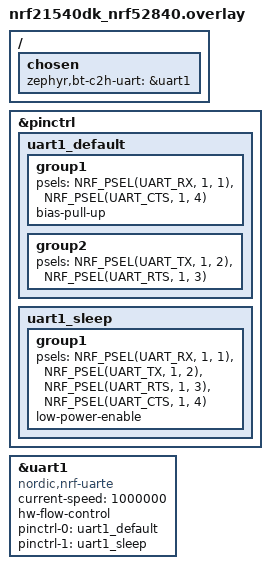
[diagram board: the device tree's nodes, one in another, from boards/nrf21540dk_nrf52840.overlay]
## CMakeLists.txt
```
# SPDX-License-Identifier: Apache-2.0

cmake_minimum_required(VERSION 3.20.0)

find_package(Zephyr REQUIRED HINTS $ENV{ZEPHYR_BASE})
project(hci_uart)

target_sources(app PRIVATE src/main.c src/status_leds.c)
```

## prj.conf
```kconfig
CONFIG_CONSOLE=n
CONFIG_STDOUT_CONSOLE=n
CONFIG_UART_CONSOLE=n
CONFIG_GPIO=y
CONFIG_SERIAL=y
CONFIG_UART_INTERRUPT_DRIVEN=y

CONFIG_SYSTEM_WORKQUEUE_STACK_SIZE=512

CONFIG_BT=y
CONFIG_BT_HCI_RAW=y
CONFIG_BT_HCI_RAW_H4=y
CONFIG_BT_HCI_RAW_H4_ENABLE=y
CONFIG_BT_MAX_CONN=16

# NOTE: this NCS/Zephyr version has no assignable CONFIG_BT_CTLR symbol
# (Kconfig error: "undefined symbol BT_CTLR"). The umbrella symbol is now
# the hidden CONFIG_HAS_BT_CTLR, auto-selected by whichever link-layer
# implementation is active; it is not user-settable. For nrf52840dk/
# nrf52840 in this tree the active controller is the Nordic SoftDevice
# Controller (DT node bt_hci_sdc, chosen as zephyr,bt-hci), selected
# automatically because DT_HAS_NORDIC_BT_HCI_SDC_ENABLED and
# SOC_SERIES_NRF52 are true - no prj.conf entry needed to enable it.
CONFIG_BT_CTLR_ASSERT_HANDLER=y

# CONFIG_BT_OBSERVER has no default-y-if-BT_HCI_RAW (unlike BT_CENTRAL/
# BT_PERIPHERAL): without it, passive scanning is not even compiled in,
# and CONFIG_BT_CTLR_SDC_SCAN_BUFFER_COUNT below stays inert (it depends
# on BT_OBSERVER).
CONFIG_BT_OBSERVER=y

# BT_CENTRAL/BT_PERIPHERAL both have default-y-if-BT_HCI_RAW already, so
# this is technically redundant, but made explicit: this firmware covers
# passive scan monitoring (Observer), the host (BlueZ) initiating GATT
# connections to discovered devices (Central), advertising so the host
# can be discovered (Broadcaster), and accepting incoming GATT
# connections (Peripheral).
CONFIG_BT_CENTRAL=y
CONFIG_BT_PERIPHERAL=y
CONFIG_BT_BROADCASTER=y

# Default TX power at boot: +8 dBm, the maximum the bare nRF52840 RADIO
# peripheral can produce (confirmed against the official register
# definition in nrf52840_bitfields.h - RADIO_TXPOWER_TXPOWER_Pos8dBm is
# the highest positive enumerator; there is no +9/+10 dBm on this chip).
# Previously left at the Kconfig default of 0 dBm.
CONFIG_BT_CTLR_TX_PWR_PLUS_8=y

# Exposes the Zephyr/Nordic vendor-specific "Read/Write TX Power Level"
# HCI commands (opcodes 0xFC0F/0xFC0E) at runtime, per connection/role
# handle. Without this, TX power is fixed at build time and those VS
# commands are rejected by the controller as Unknown HCI Command
# (status 0x01) - confirmed on hardware. Needed because BlueZ manages
# GATT connections to discovered devices and may want to tune TX power
# per link (range vs. power trade-off) rather than live with one fixed
# value for everything; also relevant once a future nRF21540 FEM
# iteration needs its own runtime power control up to +20/+21 dBm.
CONFIG_BT_CTLR_TX_PWR_DYNAMIC_CONTROL=y

# Sizing for continuous passive-scan monitoring (many devices, sustained
# LE Advertising Report stream), not generic/bursty usage:
#
# Controller-internal scan buffers (SoftDevice Controller, the active
# controller for nrf52840dk/nrf52840 in this NCS tree via the bt_hci_sdc
# DT node). These hold incoming packets/advertising reports before they
# become HCI events queued for the H4 UART driver. Raised from the
# default of 3 to the maximum of 20 to absorb bursts of overlapping
# adverts from many nearby devices without the controller dropping
# reports; cost is a few KB of RAM (~255 B/buffer worst case).
CONFIG_BT_CTLR_SDC_SCAN_BUFFER_COUNT=20

# Host-side HCI event RX queue, matched to the controller buffer count
# above per the sample's own guidance ("adjust to match Controller
# values"). This is the last stage before events are drained onto the
# UART; at the default of 10 it is the first thing to overflow under a
# sustained multi-device advertising burst. Raised to the Kconfig
# maximum (255) since this firmware's whole purpose is absorbing bursty
# advertising traffic, and the extra RAM (up to ~255 x 255 B if events
# are max-sized) is cheap compared to silently losing reports.
CONFIG_BT_BUF_EVT_RX_COUNT=255

# Maximum HCI event buffer length: raised to 255 (from the 68-byte
# default that applies without BT_EXT_ADV) so extended-advertising
# reports (long AD payloads) are never truncated.
CONFIG_BT_BUF_EVT_RX_SIZE=255
```

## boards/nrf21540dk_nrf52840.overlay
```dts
/* SPDX-License-Identifier: Apache-2.0 */

/*
 * Same HCI link as on the nRF52840-DK: uart1 at 1 Mbaud with hardware flow
 * control, uart0 left for the debug console.
 *
 * The nRF21540-DK carries an nRF52840 as its SoC, and its uart1 pinctrl is
 * identical to the plain DK's - RX on P1.01, TX on P1.02, no RTS/CTS - so
 * the same pins and the same wiring to the Pi apply. RTS/CTS are added here
 * on P1.03/P1.04, silkscreened D2/D3 on the Arduino header.
 *
 * The FEM itself needs nothing here: the board devicetree already declares
 * nrf_radio_fem with its control GPIOs (P0.17/19/20/21/22/23) and SPI, all
 * on port 0 and spi3, so nothing collides with the UART on port 1.
 */

/ {
	chosen {
		zephyr,bt-c2h-uart = &uart1;
	};
};

&pinctrl {
	uart1_default: uart1_default {
		group1 {
			psels = <NRF_PSEL(UART_RX, 1, 1)>,
				<NRF_PSEL(UART_CTS, 1, 4)>;
			bias-pull-up;
		};

		group2 {
			psels = <NRF_PSEL(UART_TX, 1, 2)>,
				<NRF_PSEL(UART_RTS, 1, 3)>;
		};
	};

	uart1_sleep: uart1_sleep {
		group1 {
			psels = <NRF_PSEL(UART_RX, 1, 1)>,
				<NRF_PSEL(UART_TX, 1, 2)>,
				<NRF_PSEL(UART_RTS, 1, 3)>,
				<NRF_PSEL(UART_CTS, 1, 4)>;
			low-power-enable;
		};
	};
};

&uart1 {
	compatible = "nordic,nrf-uarte";
	status = "okay";
	current-speed = <1000000>;
	hw-flow-control;
	pinctrl-0 = <&uart1_default>;
	pinctrl-1 = <&uart1_sleep>;
	pinctrl-names = "default", "sleep";
};
```

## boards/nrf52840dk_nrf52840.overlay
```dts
/* SPDX-License-Identifier: Apache-2.0 */

/*
 * HCI link to the Raspberry Pi runs on uart1, not uart0.
 * uart0 stays free for the J-Link virtual COM port (debug console),
 * kept separate from the physical HCI link.
 *
 * uart1 default pinctrl (nrf52840dk_nrf52840-pinctrl.dtsi) only assigns
 * RX (P1.01) and TX (P1.02); RTS/CTS are not present there and are added
 * below on P1.03 / P1.04. Chosen over P1.00/P1.09 (also free) because
 * P1.03/P1.04 are silkscreened on the DK's Arduino header as D2/D3,
 * making them easy to identify physically; D2/D3 are not used by any
 * on-board peripheral (SPI3 uses D11-D13, i.e. P1.13-15).
 */

/ {
	chosen {
		zephyr,bt-c2h-uart = &uart1;
	};
};

&pinctrl {
	uart1_default: uart1_default {
		group1 {
			psels = <NRF_PSEL(UART_RX, 1, 1)>,
				<NRF_PSEL(UART_CTS, 1, 4)>;
			bias-pull-up;
		};

		group2 {
			psels = <NRF_PSEL(UART_TX, 1, 2)>,
				<NRF_PSEL(UART_RTS, 1, 3)>;
		};
	};

	uart1_sleep: uart1_sleep {
		group1 {
			psels = <NRF_PSEL(UART_RX, 1, 1)>,
				<NRF_PSEL(UART_TX, 1, 2)>,
				<NRF_PSEL(UART_RTS, 1, 3)>,
				<NRF_PSEL(UART_CTS, 1, 4)>;
			low-power-enable;
		};
	};
};

&uart1 {
	compatible = "nordic,nrf-uarte";
	status = "okay";
	current-speed = <1000000>;
	hw-flow-control;
	pinctrl-0 = <&uart1_default>;
	pinctrl-1 = <&uart1_sleep>;
	pinctrl-names = "default", "sleep";
};
```

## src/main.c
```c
/*
 * Copyright (c) 2016 Nordic Semiconductor ASA
 * Copyright (c) 2015-2016 Intel Corporation
 *
 * SPDX-License-Identifier: Apache-2.0
 */

#include <errno.h>
#include <stddef.h>
#include <stdio.h>
#include <string.h>

#include <zephyr/kernel.h>
#include <zephyr/arch/cpu.h>
#include <zephyr/sys/byteorder.h>
#include <zephyr/logging/log_ctrl.h>
#include <zephyr/logging/log.h>
#include <zephyr/sys/util.h>

#include <zephyr/device.h>
#include <zephyr/init.h>
#include <zephyr/drivers/uart.h>

#include <zephyr/net_buf.h>
#include <zephyr/bluetooth/bluetooth.h>
#include <zephyr/bluetooth/l2cap.h>
#include <zephyr/bluetooth/hci.h>
#include <zephyr/bluetooth/buf.h>
#include <zephyr/bluetooth/hci_raw.h>
#include <zephyr/bluetooth/hci_vs.h>

#include "status_leds.h"

#define LOG_MODULE_NAME hci_uart
LOG_MODULE_REGISTER(LOG_MODULE_NAME);

static const struct device *const hci_uart_dev =
	DEVICE_DT_GET(DT_CHOSEN(zephyr_bt_c2h_uart));
static K_THREAD_STACK_DEFINE(tx_thread_stack, CONFIG_BT_HCI_TX_STACK_SIZE);
static struct k_thread tx_thread_data;
static K_FIFO_DEFINE(tx_queue);

/* RX in terms of bluetooth communication */
static K_FIFO_DEFINE(uart_tx_queue);

#define H4_CMD 0x01
#define H4_ACL 0x02
#define H4_SCO 0x03
#define H4_EVT 0x04
#define H4_ISO 0x05

/* Receiver states. */
#define ST_IDLE 0	/* Waiting for packet type. */
#define ST_HDR 1	/* Receiving packet header. */
#define ST_PAYLOAD 2	/* Receiving packet payload. */
#define ST_DISCARD 3	/* Dropping packet. */

/* Length of a discard/flush buffer.
 * This is sized to align with a Bluetooth HCI packet:
 * 1 byte H:4 header + 32 bytes ACL/event data
 * Bigger values might overflow the stack since this is declared as a local
 * variable, smaller ones will force the caller to call into discard more
 * often.
 */
#define H4_DISCARD_LEN 33

static int h4_read(const struct device *uart, uint8_t *buf, size_t len)
{
	int rx = uart_fifo_read(uart, buf, len);

	LOG_DBG("read %d req %d", rx, len);

	return rx;
}

static bool valid_type(uint8_t type)
{
	return (type == H4_CMD) | (type == H4_ACL) | (type == H4_ISO);
}

/* Function expects that type is validated and only CMD, ISO or ACL will be used. */
static uint32_t get_len(const uint8_t *hdr_buf, uint8_t type)
{
	switch (type) {
	case H4_CMD:
		return ((const struct bt_hci_cmd_hdr *)hdr_buf)->param_len;
	case H4_ISO:
		return bt_iso_hdr_len(
			sys_le16_to_cpu(((const struct bt_hci_iso_hdr *)hdr_buf)->len));
	case H4_ACL:
		return sys_le16_to_cpu(((const struct bt_hci_acl_hdr *)hdr_buf)->len);
	default:
		LOG_ERR("Invalid type: %u", type);
		return 0;
	}
}

/* Function expects that type is validated and only CMD, ISO or ACL will be used. */
static int hdr_len(uint8_t type)
{
	switch (type) {
	case H4_CMD:
		return sizeof(struct bt_hci_cmd_hdr);
	case H4_ISO:
		return sizeof(struct bt_hci_iso_hdr);
	case H4_ACL:
		return sizeof(struct bt_hci_acl_hdr);
	default:
		LOG_ERR("Invalid type: %u", type);
		return 0;
	}
}

static void rx_isr(void)
{
	static struct net_buf *buf;
	static int remaining;
	static uint8_t state;
	static uint8_t type;
	static uint8_t hdr_buf[MAX(sizeof(struct bt_hci_cmd_hdr),
			sizeof(struct bt_hci_acl_hdr))];
	int read;

	do {
		switch (state) {
		case ST_IDLE:
			/* Get packet type */
			read = h4_read(hci_uart_dev, &type, sizeof(type));
			/* since we read in loop until no data is in the fifo,
			 * it is possible that read = 0.
			 */
			if (read) {
				if (valid_type(type)) {
					status_leds_rx_activity();
					/* Get expected header size and switch
					 * to receiving header.
					 */
					remaining = hdr_len(type);
					state = ST_HDR;
				} else {
					LOG_WRN("Unknown header %d", type);
				}
			}
			break;
		case ST_HDR:
			read = h4_read(hci_uart_dev,
				       &hdr_buf[hdr_len(type) - remaining],
				       remaining);
			remaining -= read;
			if (remaining == 0) {
				/* Header received. Allocate buffer and get
				 * payload length. If allocation fails leave
				 * interrupt. On failed allocation state machine
				 * is reset.
				 */
				buf = bt_buf_get_tx(bt_buf_type_from_h4(type, BT_BUF_OUT),
						    K_NO_WAIT, NULL, 0);
				if (!buf) {
					LOG_ERR("No available command buffers!");
					state = ST_IDLE;
					return;
				}

				remaining = get_len(hdr_buf, type);

				net_buf_add_mem(buf, hdr_buf, hdr_len(type));
				if (remaining > net_buf_tailroom(buf)) {
					LOG_ERR("Not enough space in buffer");
					net_buf_unref(buf);
					state = ST_DISCARD;
				} else {
					state = ST_PAYLOAD;
				}

			}
			break;
		case ST_PAYLOAD:
			read = h4_read(hci_uart_dev, net_buf_tail(buf),
				       remaining);
			buf->len += read;
			remaining -= read;
			if (remaining == 0) {
				/* Packet received */
				LOG_DBG("putting RX packet in queue.");
				k_fifo_put(&tx_queue, buf);
				state = ST_IDLE;
			}
			break;
		case ST_DISCARD:
		{
			uint8_t discard[H4_DISCARD_LEN];
			size_t to_read = MIN(remaining, sizeof(discard));

			read = h4_read(hci_uart_dev, discard, to_read);
			remaining -= read;
			if (remaining == 0) {
				state = ST_IDLE;
			}

			break;

		}
		default:
			read = 0;
			__ASSERT_NO_MSG(0);
			break;

		}
	} while (read);
}

static void tx_isr(void)
{
	static struct net_buf *buf;
	int len;

	if (!buf) {
		buf = k_fifo_get(&uart_tx_queue, K_NO_WAIT);
		if (!buf) {
			uart_irq_tx_disable(hci_uart_dev);
			return;
		}
	}

	len = uart_fifo_fill(hci_uart_dev, buf->data, buf->len);
	net_buf_pull(buf, len);
	if (!buf->len) {
		net_buf_unref(buf);
		buf = NULL;
	}
}

static void bt_uart_isr(const struct device *unused, void *user_data)
{
	ARG_UNUSED(unused);
	ARG_UNUSED(user_data);

	while (true) {
		uart_irq_update(hci_uart_dev);

		if (uart_irq_is_pending(hci_uart_dev) <= 0) {
			break;
		}

		if (!(uart_irq_rx_ready(hci_uart_dev) ||
		      uart_irq_tx_ready(hci_uart_dev))) {
			LOG_DBG("spurious interrupt");
		}

		if (uart_irq_tx_ready(hci_uart_dev)) {
			tx_isr();
		}

		if (uart_irq_rx_ready(hci_uart_dev)) {
			rx_isr();
		}
	}
}

static void tx_thread(void *p1, void *p2, void *p3)
{
	while (1) {
		struct net_buf *buf;
		int err;

		/* Wait until a buffer is available */
		buf = k_fifo_get(&tx_queue, K_FOREVER);
		/* Pass buffer to the stack */
		err = bt_send(buf);
		if (err) {
			LOG_ERR("Unable to send (err %d)", err);
			net_buf_unref(buf);
		}

		/* Give other threads a chance to run if tx_queue keeps getting
		 * new data all the time.
		 */
		k_yield();
	}
}

/* Light LED4 on every LE Advertising Report leaving for the host, so radio
 * reception is observable on the board itself. Layout at this point is the
 * on-wire H4 frame: [0] H4 type, [1] event code, [2] param len, [3] LE
 * subevent code.
 */
static void led_flash_if_adv_report(const struct net_buf *buf)
{
	if (buf->len < 4) {
		return;
	}

	if (buf->data[0] != H4_EVT ||
	    buf->data[1] != BT_HCI_EVT_LE_META_EVENT) {
		return;
	}

	if (buf->data[3] == BT_HCI_EVT_LE_ADVERTISING_REPORT ||
	    buf->data[3] == BT_HCI_EVT_LE_EXT_ADVERTISING_REPORT) {
		status_leds_adv_report();
	}
}

static int h4_send(struct net_buf *buf)
{
	LOG_DBG("buf %p type %u len %u", buf, buf->data[0], buf->len);

	led_flash_if_adv_report(buf);
	status_leds_tx_activity();

	k_fifo_put(&uart_tx_queue, buf);
	uart_irq_tx_enable(hci_uart_dev);

	return 0;
}

#if defined(CONFIG_BT_CTLR_ASSERT_HANDLER)
void bt_ctlr_assert_handle(char *file, uint32_t line)
{
	/* Disable interrupts, this is unrecoverable */
	(void)irq_lock();

	if (IS_ENABLED(CONFIG_BT_HCI_VS_FATAL_ERROR)) {
		struct net_buf *buf;

		/* Prepare vendor specific HCI error event */
		buf = hci_vs_err_assert(file, line);
		if (buf != NULL) {
			uint32_t len;
			uint8_t *data;

			/* Disable interrupt driven, and use polling to be able to transmit while
			 * being in highest priority ISR.
			 */
			uart_irq_rx_disable(hci_uart_dev);
			uart_irq_tx_disable(hci_uart_dev);

			/* Send the event over UART */
			data = &buf->data[0];
			len = buf->len;
			while (len) {
				uart_poll_out(hci_uart_dev, *data);
				data++;
				len--;
			}
		} else {
			LOG_ERR("Can't create Fatal Error HCI event: %s at %d", __FILE__, __LINE__);
		}

		LOG_ERR("Halting system");
	} else {
		LOG_ERR("Controller assert in: %s at %d", file, line);
	}

	/* Flush the logs before locking the CPU */
	LOG_PANIC();

	while (true) {
		k_cpu_idle();
	};

	CODE_UNREACHABLE;
}
#endif /* CONFIG_BT_CTLR_ASSERT_HANDLER */

#if defined(CONFIG_BT_HCI_VS_FATAL_ERROR)
void k_sys_fatal_error_handler(unsigned int reason, const struct arch_esf *esf)
{
	/* Disable interrupts, this is unrecoverable */
	(void)irq_lock();

	/* Generate an error event only when there is a stack frame */
	if (esf != NULL) {
		struct net_buf *buf;

		/* Prepare vendor specific HCI error event */
		buf = hci_vs_err_stack_frame(reason, esf);
		if (buf != NULL) {
			uint32_t len;
			uint8_t *data;

			/* Disable interrupt driven, and use polling to be able to transmit while
			 * being in highest priority ISR.
			 */
			uart_irq_rx_disable(hci_uart_dev);
			uart_irq_tx_disable(hci_uart_dev);

			/* Send the event over UART */
			data = &buf->data[0];
			len = buf->len;
			while (len) {
				uart_poll_out(hci_uart_dev, *data);
				data++;
				len--;
			}
		} else {
			LOG_ERR("Can't create Fatal Error HCI event.\n");
		}
	}

	LOG_ERR("Halting system");

	/* Flush the logs before locking the CPU */
	LOG_PANIC();

	while (true) {
		k_cpu_idle();
	};

	CODE_UNREACHABLE;
}
#endif /* CONFIG_BT_HCI_VS_FATAL_ERROR */

static int hci_uart_init(void)
{
	LOG_DBG("");

	if (!device_is_ready(hci_uart_dev)) {
		LOG_ERR("HCI UART %s is not ready", hci_uart_dev->name);
		return -EINVAL;
	}

	uart_irq_rx_disable(hci_uart_dev);
	uart_irq_tx_disable(hci_uart_dev);

	uart_irq_callback_set(hci_uart_dev, bt_uart_isr);

	uart_irq_rx_enable(hci_uart_dev);

	return 0;
}

SYS_INIT(hci_uart_init, APPLICATION, CONFIG_KERNEL_INIT_PRIORITY_DEVICE);

int main(void)
{
	/* incoming events and data from the controller */
	static K_FIFO_DEFINE(rx_queue);
	int err;

	LOG_DBG("Start");
	__ASSERT(hci_uart_dev, "UART device is NULL");

	/* Enable the raw interface, this will in turn open the HCI driver */
	bt_enable_raw(&rx_queue);

	if (IS_ENABLED(CONFIG_BT_WAIT_NOP)) {
		/* Issue a Command Complete with NOP */
		int i;

		const struct {
			const uint8_t h4;
			const uint8_t evt;
			const uint8_t len;
			const struct bt_hci_evt_cmd_complete cc;
		} __packed cc_evt = {
			.h4 = H4_EVT,
			.evt = BT_HCI_EVT_CMD_COMPLETE,
			.len = sizeof(struct bt_hci_evt_cmd_complete),
			.cc = {
				.ncmd = 1,
				.opcode = sys_cpu_to_le16(BT_OP_NOP),
			},
		};

		for (i = 0; i < sizeof(cc_evt); i++) {
			uart_poll_out(hci_uart_dev,
				      *(((const uint8_t *)&cc_evt)+i));
		}
	}

	/* Spawn the TX thread and start feeding commands and data to the
	 * controller
	 */
	k_thread_create(&tx_thread_data, tx_thread_stack,
			K_THREAD_STACK_SIZEOF(tx_thread_stack), tx_thread,
			NULL, NULL, NULL, K_PRIO_COOP(7), 0, K_NO_WAIT);
	k_thread_name_set(&tx_thread_data, "HCI uart TX");

	while (1) {
		struct net_buf *buf;

		buf = k_fifo_get(&rx_queue, K_FOREVER);
		err = h4_send(buf);
		if (err) {
			LOG_ERR("Failed to send");
		}
	}
	return 0;
}
```

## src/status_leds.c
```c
/* SPDX-License-Identifier: Apache-2.0 */

#include <zephyr/kernel.h>
#include <zephyr/device.h>
#include <zephyr/drivers/gpio.h>
#include <zephyr/init.h>

#include "status_leds.h"

#define HEARTBEAT_PERIOD_MS 500  /* toggles every 500 ms -> ~1 Hz blink */
#define FLASH_DURATION_MS   20   /* long enough to be visible, short enough
                                  * not to merge under sustained traffic
                                  */

static const struct gpio_dt_spec led_heartbeat =
	GPIO_DT_SPEC_GET(DT_ALIAS(led0), gpios);
static const struct gpio_dt_spec led_uart_tx =
	GPIO_DT_SPEC_GET(DT_ALIAS(led1), gpios);
static const struct gpio_dt_spec led_uart_rx =
	GPIO_DT_SPEC_GET(DT_ALIAS(led2), gpios);
static const struct gpio_dt_spec led_adv =
	GPIO_DT_SPEC_GET(DT_ALIAS(led3), gpios);

static bool leds_ready;

static void heartbeat_fn(struct k_timer *timer);
static void tx_off_fn(struct k_timer *timer);
static void rx_off_fn(struct k_timer *timer);
static void adv_off_fn(struct k_timer *timer);

K_TIMER_DEFINE(heartbeat_timer, heartbeat_fn, NULL);
K_TIMER_DEFINE(tx_off_timer, tx_off_fn, NULL);
K_TIMER_DEFINE(rx_off_timer, rx_off_fn, NULL);
K_TIMER_DEFINE(adv_off_timer, adv_off_fn, NULL);

static void heartbeat_fn(struct k_timer *timer)
{
	ARG_UNUSED(timer);
	gpio_pin_toggle_dt(&led_heartbeat);
}

static void tx_off_fn(struct k_timer *timer)
{
	ARG_UNUSED(timer);
	gpio_pin_set_dt(&led_uart_tx, 0);
}

static void rx_off_fn(struct k_timer *timer)
{
	ARG_UNUSED(timer);
	gpio_pin_set_dt(&led_uart_rx, 0);
}

static void adv_off_fn(struct k_timer *timer)
{
	ARG_UNUSED(timer);
	gpio_pin_set_dt(&led_adv, 0);
}

static void flash(const struct gpio_dt_spec *led, struct k_timer *off_timer)
{
	if (!leds_ready) {
		return;
	}

	gpio_pin_set_dt(led, 1);
	/* Restarts the timer if a new event arrives while still lit, so the
	 * LED stays on through a burst rather than flickering per packet.
	 */
	k_timer_start(off_timer, K_MSEC(FLASH_DURATION_MS), K_NO_WAIT);
}

void status_leds_tx_activity(void)
{
	flash(&led_uart_tx, &tx_off_timer);
}

void status_leds_rx_activity(void)
{
	flash(&led_uart_rx, &rx_off_timer);
}

void status_leds_adv_report(void)
{
	flash(&led_adv, &adv_off_timer);
}

static int status_leds_init(void)
{
	const struct gpio_dt_spec *leds[] = {
		&led_heartbeat, &led_uart_tx, &led_uart_rx, &led_adv,
	};

	for (size_t i = 0; i < ARRAY_SIZE(leds); i++) {
		if (!gpio_is_ready_dt(leds[i])) {
			return -ENODEV;
		}

		if (gpio_pin_configure_dt(leds[i], GPIO_OUTPUT_INACTIVE) < 0) {
			return -EIO;
		}
	}

	leds_ready = true;
	k_timer_start(&heartbeat_timer, K_MSEC(HEARTBEAT_PERIOD_MS),
		      K_MSEC(HEARTBEAT_PERIOD_MS));

	return 0;
}

SYS_INIT(status_leds_init, APPLICATION, CONFIG_APPLICATION_INIT_PRIORITY);
```

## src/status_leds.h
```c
/* SPDX-License-Identifier: Apache-2.0 */

#ifndef STATUS_LEDS_H_
#define STATUS_LEDS_H_

/* Visual diagnostics on the DK's four LEDs, so board state can be read
 * without a debug probe attached:
 *
 *   LED1  heartbeat, ~1 Hz          -> MCU powered and scheduler running
 *   LED2  brief flash on UART TX    -> HCI traffic leaving towards the host
 *   LED3  brief flash on UART RX    -> HCI traffic arriving from the host
 *   LED4  brief flash per LE adv report -> radio actually receiving
 *
 * All flash helpers are ISR-safe.
 */

void status_leds_tx_activity(void);
void status_leds_rx_activity(void);
void status_leds_adv_report(void);

#endif /* STATUS_LEDS_H_ */
```
